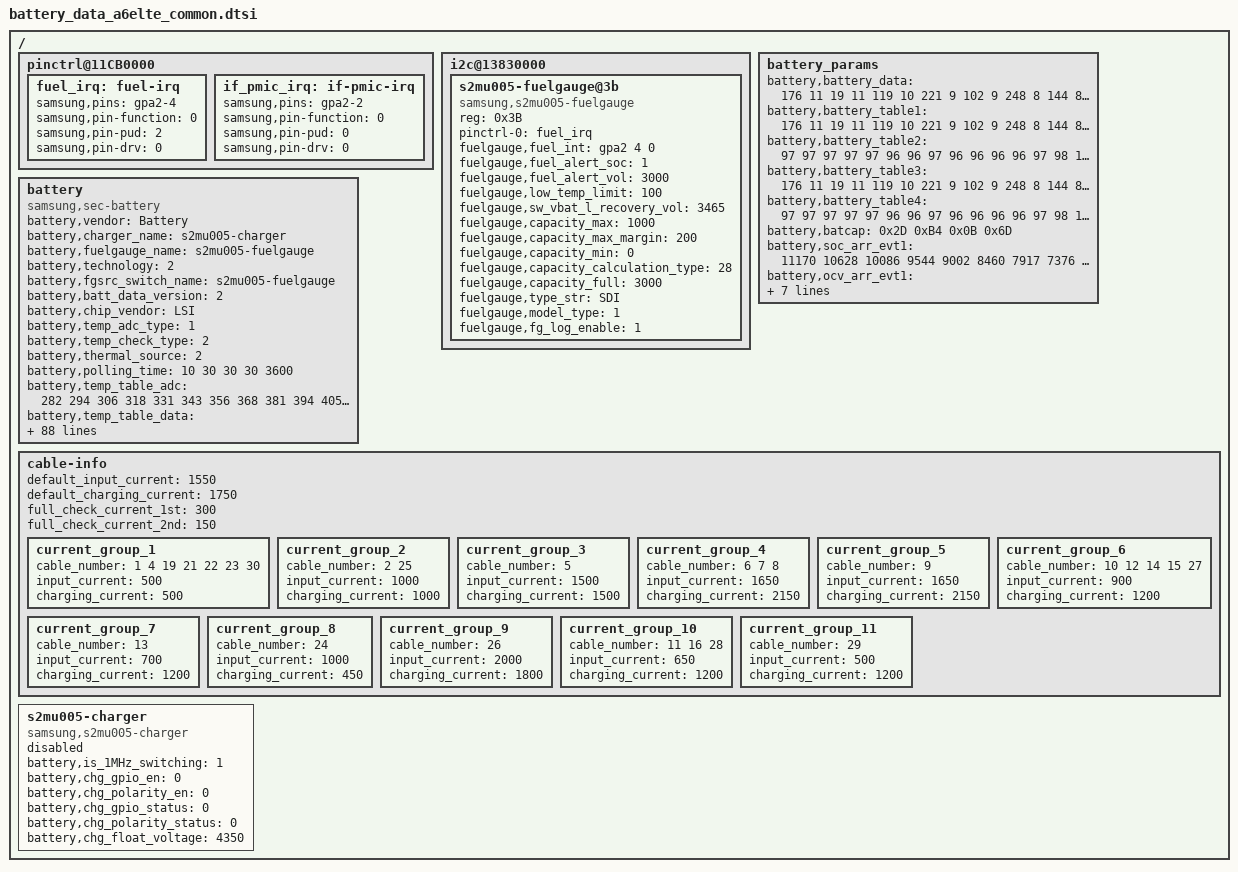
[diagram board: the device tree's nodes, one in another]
/*
 * A6 2018 US Battery parameters device tree file for board IDs 04 and higher
 *
 * Copyright (C) 2018 Samsung Electronics, Inc.
 *
 * This program is free software; you can redistribute it and/or
 * modify it under the terms of the GNU General Public License
 * as published by the Free Software Foundation; either version 2
 * of the License, or (at your option) any later version.
 *
 * This program is distributed in the hope that it will be useful,
 * but WITHOUT ANY WARRANTY; without even the implied warranty of
 * MERCHANTABILITY or FITNESS FOR A PARTICULAR PURPOSE.  See the
 * GNU General Public License for more details.
 *
 * You should have received a copy of the GNU General Public License
 * along with this program. If not, see <http://www.gnu.org/licenses/>.
 *
 */

/ {
	pinctrl@11CB0000 {
		fuel_irq: fuel-irq {
			samsung,pins = "gpa2-4";
			samsung,pin-function = <0>;
			samsung,pin-pud = <2>;
			samsung,pin-drv = <0>;
		};

		if_pmic_irq: if-pmic-irq {
			samsung,pins = "gpa2-2";
			samsung,pin-function = <0>;
			samsung,pin-pud = <0>;
			samsung,pin-drv = <0>;
		};
	};

	i2c@13830000 {
		status = "okay";
		s2mu005-fuelgauge@3b {
			compatible = "samsung,s2mu005-fuelgauge";
			reg = <0x3B>;
			pinctrl-names = "default";
			pinctrl-0 = <&fuel_irq>;
			fuelgauge,fuel_int = <&gpa2 4 0>;
			fuelgauge,fuel_alert_soc = <1>;
			fuelgauge,fuel_alert_vol = <3000>;
			fuelgauge,low_temp_limit = <100>;
			fuelgauge,sw_vbat_l_recovery_vol = <3465>;
			fuelgauge,capacity_max = <1000>;
			fuelgauge,capacity_max_margin = <200>;
			fuelgauge,capacity_min = <0>;
			fuelgauge,capacity_calculation_type = <28>;
			fuelgauge,capacity_full = <3000>;
			fuelgauge,type_str = "SDI";
			fuelgauge,model_type = <1>;
			fuelgauge,fg_log_enable = <1>;
		};
	};

	battery_params {
			battery,battery_data =
			<
				/***** battery data for 4.35 *****/
				/* battery,battery_table3 */
				176 11 19 11 119 10 221 9 102 9
				248 8 144 8 28 8 191 7 128 7
				40 7 211 6 154 6 114 6 83 6
				60 6 31 6 249 5 196 5 146 5
				28 5 209 1 240 8 129 8 18 8
				163 7 52 7 197 6 86 6 231 5
				120 5 9 5 154 4 43 4 188 3
				77 3 222 2 111 2 0 2 145 1
				34 1 179 0 68 0 213 15

				/* battery,battery_table4 */
				97 97 97 97 97 96 96 97 96 96
				96 96 97 98 100 101 104 107 113 124
				138 206

				/* battery,batcap */
				0x2D 0xB4 0x0B 0x6D /* [0x0F] [0x0E] [0x11] [0x10] */
				/* battery,accum */
				0x3B 0x08 /* [0x44] [0x45] */

				/* battery,soc_arr_val */
				11170 10628 10086 9544 9002 8460 7917 7376 6834 6292
				5750 5208 4666 4124 3582 3040 2498 1956 1414 872
				330 (-212)
				/* battery,ocv_arr_val */
				44608 43844 43080 42328 41746 41210 40702 40134 39682 39376
				38944 38530 38251 38056 37907 37791 37650 37464 37208 36964
				36386 32272

				/***** battery data for 4.33 *****/
				/* battery,battery_table3 */
				175 11 19 11 119 10 221 9 101 9
				248 8 144 8 28 8 191 7 128 7
				40 7 211 6 154 6 114 6 84 6
				60 6 31 6 249 5 196 5 146 5
				28 5 209 1 216 8 106 8 252 7
				142 7 33 7 179 6 69 6 215 5
				105 5 251 4 141 4 32 4 178 3
				68 3 214 2 104 2 250 1 140 1
				30 1 177 0 67 0 213 15

				/* battery,battery_table4 */
				97 97 97 97 97 97 96 97 96 96
				96 96 97 98 100 101 104 107 113 124
				138 104

				/* battery,batcap */
				0x2D 0xA0 0x0B 0x68 /* [0x0F] [0x0E] [0x11] [0x10] */

				/* battery,accum */
				0x3B 0x08 /* [0x44] [0x45] */

				/* battery,soc_arr_val */
				11054 10518 9982 9445 8909 8372 7836 7300 6763 6227
				5689 5154 4618 4081 3545 3008 2472 1936 1399 863
				325 (-210)
				/* battery,ocv_arr_val */
				44607 43844 43080 42329 41745 41211 40702 40134 39682 39376
				38945 38531 38251 38056 37908 37791 37650 37464 37208 36964
				36386 32272

				/***** battery data for 4.31 *****/
				/* battery,battery_table3 */
				176 11 19 11 119 10 221 9 101 9
				248 8 144 8 28 8 191 7 128 7
				40 7 211 6 154 6 114 6 84 6
				60 6 31 6 249 5 196 5 146 5
				28 5 209 1 240 8 129 8 18 8
				163 7 52 7 197 6 86 6 231 5
				120 5 9 5 154 4 43 4 188 3
				77 3 222 2 111 2 0 2 145 1
				34 1 179 0 68 0 213 15

				/* battery,battery_table4 */
				97 97 97 97 97 97 96 97 96 96
				96 96 97 98 100 101 104 107 113 124
				138 104

				/* battery,batcap */
				0x2D 0x00 0x0B 0x40 /* [0x0F] [0x0E] [0x11] [0x10] */
				/* battery,accum */
				0x3B 0x08 /* [0x44] [0x45] */

				/* battery,soc_arr_val */
				11170 10628 10086 9544 9002 8460 7917 7376 6834 6292
				5750 5208 4666 4124 3582 3040 2498 1956 1414 872
				330 (-212)
				/* battery,ocv_arr_val */
				44608 43844 43080 42328 41745 41210 40702 40134 39682 39376
				38944 38531 38251 38056 37908 37792 37650 37464 37208 36964
				36386 32272

				/***** battery data for 4.29 *****/
				/* battery,battery_table3 */
				175 11 19 11 119 10 221 9 102 9
				248 8 144 8 28 8 191 7 128 7
				40 7 211 6 154 6 114 6 84 6
				60 6 31 6 249 5 196 5 146 5
				28 5 209 1 16 9 160 8 47 8
				190 7 78 7 221 6 109 6 252 5
				139 5 27 5 170 4 58 4 201 3
				89 3 232 2 119 2 7 2 150 1
				38 1 181 0 69 0 212 15

				/* battery,battery_table4 */
				97 97 97 97 97 97 96 97 96 96
				96 96 97 98 100 101 104 107 113 124
				138 104

				/* battery,batcap */
				0x2C 0x60 0x0B 0x18 /* [0x0F] [0x0E] [0x11] [0x10] */

				/* battery,accum */
				0x3B 0x08 /* [0x44] [0x45] */

				/* battery,soc_arr_val */
				11329 10779 10229 9680 9130 8580 8031 7481 6931 6381
				5832 5282 4732 4183 3633 3083 2533 1984 1434 884
				335 (-214)

				/* battery,ocv_arr_val */
				44607 43844 43080 42328 41746 41210 40704 40134 39682 39376
				38945 38531 38251 38056 37908 37792 37650 37464 37208 36964
				36387 32272

				/***** battery data for 4.24 *****/
				/* battery,battery_table3 */
				176 11 19 11 119 10 221 9 101 9
				248 8 144 8 28 8 191 7 128 7
				40 7 211 6 154 6 114 6 84 6
				60 6 31 6 249 5 196 5 146 5
				28 5 209 1 146 9 27 9 164 8
				46 8 183 7 64 7 201 6 82 6
				219 5 100 5 237 4 119 4 0 4
				137 3 18 3 155 2 36 2 173 1
				54 1 191 0 72 0 210 15

				/* battery,battery_table4 */
				97 97 97 97 97 97 96 97 96 96
				96 96 97 98 100 101 104 107 113 124
				138 104

				/* battery,batcap */
				0x2A 0x80 0x0A 0xA0 /* [0x0F] [0x0E] [0x11] [0x10] */

				/* battery,accum */
				0x3B 0x08 /* [0x44] [0x45] */

				/* battery,soc_arr_val */
				11964 11384 10803 10223 9642 9062 8481 7901 7320 6740
				6159 5578 4998 4417 3837 3256 2676 2095 1515 934
				354 (-227)

				/* battery,ocv_arr_val */
				44608 43844 43080 42328 41745 41210 40702 40134 39682 39376
				38944 38531 38251 38056 37908 37792 37650 37464 37208 36964
				36387 32272
			>;

			battery,battery_table1 = <
					176 11 19 11 119 10 221 9 102 9
					248 8 144 8 28 8 191 7 128 7
					40 7 211 6 154 6 114 6 83 6
					60 6 31 6 249 5 196 5 146 5
					28 5 209 1 240 8 129 8 18 8
					163 7 52 7 197 6 86 6 231 5
					120 5 9 5 154 4 43 4 188 3
					77 3 222 2 111 2 0 2 145 1
					34 1 179 0 68 0 213 15
					>;

			battery,battery_table2 = <
					97 97 97 97 97 96 96 97 96 96
					96 96 97 98 100 101 104 107 113 124
					138 206
					>;

			battery,battery_table3 = <
					176 11 19 11 119 10 221 9 102 9
					248 8 144 8 28 8 191 7 128 7
					40 7 211 6 154 6 114 6 83 6
					60 6 31 6 249 5 196 5 146 5
					28 5 209 1 240 8 129 8 18 8
					163 7 52 7 197 6 86 6 231 5
					120 5 9 5 154 4 43 4 188 3
					77 3 222 2 111 2 0 2 145 1
					34 1 179 0 68 0 213 15
					>;

			battery,battery_table4 = <
					97 97 97 97 97 96 96 97 96 96
					96 96 97 98 100 101 104 107 113 124
					138 206
					>;

			battery,batcap = <0x2D 0xB4 0x0B 0x6D>; /* [0x0F] [0x0E] [0x11] [0x10] */

			battery,soc_arr_evt1 = <
					11170 10628 10086 9544 9002 8460 7917 7376 6834 6292
					5750 5208 4666 4124 3582 3040 2498 1956 1414 872
					330 (-212)
					>;
			battery,ocv_arr_evt1 = <
					44608 43844 43080 42328 41746 41210 40702 40134 39682 39376
					38944 38530 38251 38056 37907 37791 37650 37464 37208 36964
					36386 32272
					>;

			battery,soc_arr_evt2 = <
					11170 10628 10086 9544 9002 8460 7917 7376 6834 6292
					5750 5208 4666 4124 3582 3040 2498 1956 1414 872
					330 (-212)
					>;
			battery,ocv_arr_evt2 = <
					44608 43844 43080 42328 41746 41210 40702 40134 39682 39376
					38944 38530 38251 38056 37907 37791 37650 37464 37208 36964
					36386 32272
					>;

			battery,FG_Accumulative_rate_evt2 = <0x3B 0x08>; /* 0x44 0x45 */
			battery,data_ver = <0x04>;
	};

	battery {
		status = "okay";
		compatible = "samsung,sec-battery";

		pinctrl-names = "default";

		battery,vendor = "Battery";
		battery,charger_name = "s2mu005-charger";
		battery,fuelgauge_name = "s2mu005-fuelgauge";
		battery,technology = <2>; /* POWER_SUPPLY_TECHNOLOGY_LION */
		battery,fgsrc_switch_name = "s2mu005-fuelgauge"; /* Fuelgauge voltage source */

		battery,batt_data_version = <2>;

		battery,chip_vendor = "LSI";
		battery,temp_adc_type = <1>; /* SEC_BATTERY_ADC_TYPE_AP */

		battery,temp_check_type = <2>; /* SEC_BATTERY_TEMP_CHECK_TEMP */

		battery,thermal_source = <2>; /* SEC_BATTERY_THERMAL_SOURCE_ADC */

		battery,polling_time = <10 30 30 30 3600>;

		battery,temp_table_adc = <
					282 294 306 318 331 343 356 368 381 394
					405 416 426 437 448 464 480 495 511 527
					544 560 577 593 610 631 652 673 694 715
					740 765 791 816 841 869 897 924 952 980
					1012 1044 1076 1108 1140 1174 1208 1241 1275 1309
					1347 1385 1422 1460 1498 1542 1586 1631 1675 1719
					1763 1807 1851 1895 1939 1985 2032 2078 2125 2171
					2222 2273 2323 2374 2425 2469 2513 2557 2601 2645
					2683 2721 2758 2796 2834 2878 2922 2967 3011 3055
					3094 3133 3171 3210 3249 3279 3309 3340 3370 3400
					3427 3454 3482 3509 3536
					3561 3582 3602 3622 3643 3663
					>;
		battery,temp_table_data = <
					900 890 880 870 860 850 840 830 820 810
					800 790 780 770 760 750 740 730 720 710
					700 690 680 670 660 650 640 630 620 610
					600 590 580 570 560 550 540 530 520 510
					500 490 480 470 460 450 440 430 420 410
					400 390 380 370 360 350 340 330 320 310
					300 290 280 270 260 250 240 230 220 210
					200 190 180 170 160 150 140 130 120 110
					100 90 80 70 60 50 40 30 20 10
					0 (-10) (-20) (-30) (-40) (-50) (-60) (-70) (-80) (-90)
					(-100) (-110) (-120) (-130) (-140)
					(-150) (-160) (-170) (-180) (-190) (-200)
					>;

		battery,inbat_voltage = <1>;

		battery,inbat_voltage_table_adc = <2839 2822 2803 2777 2751 2708 2694 2670 2650 2612
						2591 2558 2530 2501 2469 2445 2424 2393 2351 2335
						2296 2275>;
		battery,inbat_voltage_table_data = <4400 4380 4350 4300 4250 4200 4150 4100 4050 4000
						3950 3900 3850 3800 3750 3700 3650 3600 3550 3500
						3450 3400>;

		battery,adc_check_count = <5>;

		battery,cable_check_type = <4>; /* SEC_BATTERY_CABLE_CHECK_PSY */
		battery,cable_source_type = <1>; /* SEC_BATTERY_CABLE_SOURCE_EXTERNAL */
		battery,polling_type = <1>; /* SEC_BATTERY_MONITOR_ALARM */
		battery,monitor_initial_count = <0>;

		battery,pre_afc_input_current = <500>;

		battery,battery_check_type = <0>; /* SEC_BATTERY_CHECK_NONE */
		battery,check_count = <0>;

		battery,ovp_uvlo_check_type = <3>; /* SEC_BATTERY_OVP_UVLO_CHGPOLLING */

		battery,temp_check_count = <1>;
		battery,temp_highlimit_threshold_event = <800>;
		battery,temp_highlimit_recovery_event = <750>;
		battery,temp_high_threshold_event = <500>;
		battery,temp_high_recovery_event = <450>;
		battery,temp_low_threshold_event = <0>;
		battery,temp_low_recovery_event = <50>;
		battery,temp_highlimit_threshold_normal = <800>;
		battery,temp_highlimit_recovery_normal = <750>;
		battery,temp_high_threshold_normal = <500>;
		battery,temp_high_recovery_normal = <450>;
		battery,temp_low_threshold_normal = <0>;
		battery,temp_low_recovery_normal = <50>;
		battery,temp_highlimit_threshold_lpm = <800>;
		battery,temp_highlimit_recovery_lpm = <750>;
		battery,temp_high_threshold_lpm = <500>;
		battery,temp_high_recovery_lpm = <450>;
		battery,temp_low_threshold_lpm = <0>;
		battery,temp_low_recovery_lpm = <50>;
		battery,wpc_high_threshold_normal = <450>;
		battery,wpc_high_recovery_normal = <400>;
		battery,wpc_low_threshold_normal = <0>;
		battery,wpc_low_recovery_normal = <50>;

		battery,full_check_type = <2>; /* SEC_BATTERY_FULLCHARGED_FG_CURRENT */
		battery,full_check_type_2nd = <2>; /* SEC_BATTERY_FULLCHARGED_FG_CURRENT */
		battery,full_check_count = <1>;
		battery,chg_gpio_full_check = <0>;
		battery,chg_polarity_full_check = <1>;

		/* SEC_BATTERY_FULL_CONDITION_SOC |
		 * SEC_BATTERY_FULL_CONDITION_NOTIMEFULL |
		 * SEC_BATTERY_FULL_CONDITION_VCELL
		 */
		battery,full_condition_type = <13>;
		battery,full_condition_soc = <93>;
		battery,full_condition_vcell = <4250>;

		battery,recharge_check_count = <1>;
		battery,recharge_condition_type = <4>; /* SEC_BATTERY_RECHARGE_CONDITION_VCELL */
		battery,recharge_condition_soc = <98>;
		battery,recharge_condition_vcell = <4250>;

		battery,charging_total_time = <14400>;
		battery,hv_charging_total_time = <10800>;
		battery,normal_charging_total_time = <18000>;
		battery,usb_charging_total_time = <36000>;
		battery,recharging_total_time = <5400>;
		battery,charging_reset_time = <0>;

		battery,chg_float_voltage = <4350>;

		battery,swelling_high_temp_block = <410>;
		battery,swelling_high_temp_recov = <390>;
		battery,swelling_wc_high_temp_recov = <390>;
		battery,swelling_low_temp_block_1st = <150>;
		battery,swelling_low_temp_recov_1st = <200>;
		battery,swelling_low_temp_block_2nd = <50>;
		battery,swelling_low_temp_recov_2nd = <100>;

		battery,swelling_low_temp_current = <700>;	/* 0.3C */
		battery,swelling_low_temp_topoff = <150>;	/* 0.05C */
		battery,swelling_high_temp_current = <1050>;	/* 0.45C */
		battery,swelling_high_temp_topoff = <150>;	/* 0.05C */
		battery,swelling_wc_high_temp_current = <700>;	/* 0.3C */
		battery,swelling_wc_low_temp_current = <700>;	/* 0.3C */

		battery,swelling_drop_float_voltage = <4150>;
		battery,swelling_high_rechg_voltage = <4000>;
		battery,swelling_low_rechg_voltage = <4000>;

		battery,siop_event_check_type = <1>;
		battery,siop_call_cv_current = <330>;
		battery,siop_call_cc_current = <330>;

		battery,siop_input_limit_current = <1200>;
		battery,siop_charging_limit_current = <1000>;

		battery,battery_full_capacity = <3000>;

		/* cycle, chg_float_voltage, recharge_condition_vcell, full_condition_vcell, full_condition_soc */
		battery,age_data = <0 4350 4250 4250 93	/*4.35*/
				200 4330 4230 4230 92	/*4.33*/
				250 4310 4210 4210 91	/*4.31*/
				300 4290 4190 4190 90	/*4.29*/
				1000 4240 4140 4140 89	/*4.24*/
				>;

		battery,standard_curr = <1750>;
		battery,expired_time = <13800>; /* 160 + 70 minutes */
		battery,recharging_expired_time = <5400>;

		battery,cisd_max_voltage_thr = <5000>; /* battery ovp detection voltage */

		battery,recovery_cable;

		io-channels = <&exynos_adc 1>, <&exynos_adc 2>;
		io-channel-names = "adc-temp", "adc-in-bat";
		#io-channel-cells = <5>;
		io-channel-ranges;
	};

/* sec_battery_cable
 *   0	UNKNOWN,
 *   1	NONE,
 *   2	PREPARE_TA,
 *   3	TA,
 *   4	USB,
 *   5	USB_CDP,
 *   6	9V_TA,
 *   7	9V_ERR,
 *   8	9V_UNKNOWN,
 *   9	12V_TA,
 *  10	WIRELESS,
 *  11	HV_WIRELESS,
 *  12	PMA_WIRELESS,
 *  13	WIRELESS_PACK,
 *  14	WIRELESS_PACK_TA,
 *  15	WIRELESS_STAND,
 *  16	WIRELESS_HV_STAND,
 *  17	QC20,
 *  18	QC30,
 *  19	PDIC,
 *  20	UARTOFF,
 *  21	OTG,
 *  22	LAN_HUB,
 *  23	POWER_SHARING,
 *  24	HMT_CONNECTED,
 *  25	HMT_CHARGE,
 *  26	HV_TA_CHG_LIMIT,
 *  27	WIRELESS_VEHICLE,
 *  28	WIRELESS_HV_VEHICLE,
 *  29	PREPARE_WIRELESS_HV,
 *  30  TIMEOUT,
 *  31	SMART_OTG,
 *  32	SMART_NOTG,
 *  33	FACTORY_UART,
 *  34	CABLE_MAX,
 */
	cable-info {
		default_input_current = <1550>;
		default_charging_current = <1750>;
		full_check_current_1st = <300>;
		full_check_current_2nd = <150>;

		current_group_1 {
			cable_number = <1 4 19 21 22 23 30>;
			input_current = <500>;
			charging_current = <500>;
		};

		current_group_2 {
			cable_number = <2 25>;
			input_current = <1000>;
			charging_current = <1000>;
		};

		current_group_3 {
			cable_number = <5>;
			input_current = <1500>;
			charging_current = <1500>;
		};

		current_group_4 {
			cable_number = <6 7 8>;
			input_current = <1650>;
			charging_current = <2150>;
		};

		current_group_5 {
			cable_number = <9>;
			input_current = <1650>;
			charging_current = <2150>;
		};

		current_group_6 {
			cable_number = <10 12 14 15 27>;
			input_current = <900>;
			charging_current = <1200>;
		};

		current_group_7 {
			cable_number = <13>;
			input_current = <700>;
			charging_current = <1200>;
		};

		current_group_8 {
			cable_number = <24>;
			input_current = <1000>;
			charging_current = <450>;
		};

		current_group_9 {
			cable_number = <26>;
			input_current = <2000>;
			charging_current = <1800>;
		};

		current_group_10 {
			cable_number = <11 16 28>;
			input_current = <650>;
			charging_current = <1200>;
		};

		current_group_11 {
			cable_number = <29>;
			input_current = <500>;
			charging_current = <1200>;
		};
	};

	s2mu005-charger {
		status = "disable";
		compatible = "samsung,s2mu005-charger";
		battery,is_1MHz_switching = <1>;
		battery,chg_gpio_en = <0>;
		battery,chg_polarity_en = <0>;
		battery,chg_gpio_status = <0>;
		battery,chg_polarity_status = <0>;
		battery,chg_float_voltage = <4350>;
	};
};
